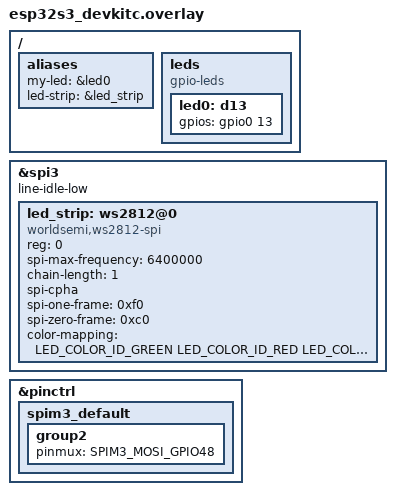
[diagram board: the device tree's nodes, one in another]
#include <zephyr/dt-bindings/led/led.h>

/ {
	aliases {
		my-led = &led0;
		led-strip = &led_strip;
	};
	
	leds {
		compatible = "gpio-leds";
		led0: d13 {
			gpios = <&gpio0 13 GPIO_ACTIVE_HIGH>;
		};
	};
};

&spi3 {
	/* Workaround to support WS2812 driver */
	line-idle-low;
	
	led_strip: ws2812@0 {
		// /opt/toolchains/zephyr/dts/bindings/led_strip/worldsemi,ws2812-spi.yaml
		// /opt/toolchains/zephyr/dts/bindings/spi/spi-device.yaml
		// /opt/toolchains/zephyr/dts/bindings/led_strip/ws2812.yaml
		// https://wp.josh.com/2014/05/13/ws2812-neopixels-are-not-so-finicky-once-you-get-to-know-them/
		compatible = "worldsemi,ws2812-spi";
		
		/* SPI */
		reg = <0>; /* ignored, but necessary for SPI bindings */
		spi-max-frequency = <6400000>;
		
		/* WS2812 */
		chain-length = <1>;
		spi-cpha;
		spi-one-frame = <0xf0>; /* 11110000: 625 ns high and 625 ns low */
		spi-zero-frame = <0xc0>; /* 11000000: 312.5 ns high and 937.5 ns low */
		color-mapping = <LED_COLOR_ID_GREEN
		LED_COLOR_ID_RED
		LED_COLOR_ID_BLUE>;
	};
};

&pinctrl {
	spim3_default: spim3_default {
		group2 {
			pinmux = <SPIM3_MOSI_GPIO48>;
		};
	};
};
